# B6x register map
Vendor: XiaoMan; Series: B6 SOC; File version: 20260307
CPU: CM0+ r0p0, little endian, no MPU, no FPU, 2 interrupt priority bits
Registers are 32-bit, read-write, reset 0x0 unless marked. A register's access mark holds for its fields unless they carry their own. Offsets are from the block's base; [hi:lo] are bit positions.

## AON — Always On Domain
Base 0x40030000
0x00 BACKUP0 — valid-bit:16, can't be reset by pin reset, por12_bk_stb
0x04 BACKUP1 — valid-bit:8, can't be reset by pin reset, por12_bk_stb
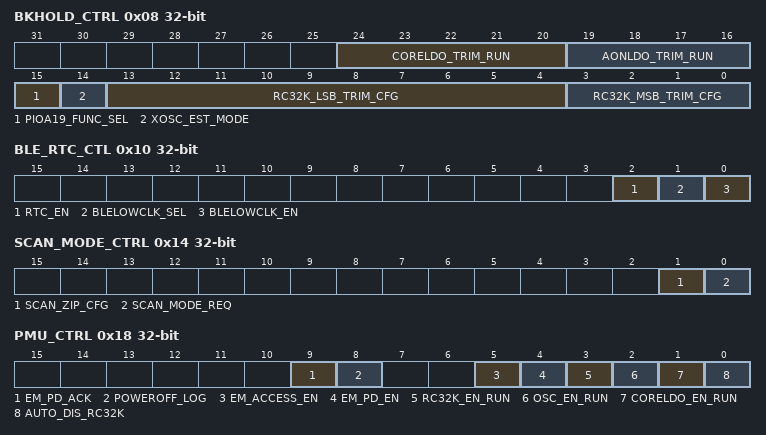
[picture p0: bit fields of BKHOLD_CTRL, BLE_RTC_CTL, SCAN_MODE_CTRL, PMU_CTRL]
0x08 BKHOLD_CTRL
  [24:20] CORELDO_TRIM_RUN — CORE LDO trim, used when ST_RUN
  [19:16] AONLDO_TRIM_RUN — LDOBK_TRIM, inverter the high two bits
  [15] PIOA19_FUNC_SEL
    1=Enable (pioa19 used as GPIO, can't be reset by pin reset); 0=Disable (pioa19 used as reset pin)
  [14] XOSC_EST_MODE
    1=Enable (extarnal clock through XOSC16M_IN PAD into chip and XOSC16M_OUT PAD is not driven by XOSC16M); 0=Disable (the XOSC16M_IN and XOSC16M_OUT are connected with crystal oscillator)
  [13:4] RC32K_LSB_TRIM_CFG
  [3:0] RC32K_MSB_TRIM_CFG
0x0C BACKUP2 — valid-bit:8, can't be reset by pin reset, por12_bk_stb
0x10 BLE_RTC_CTL
  [2] RTC_EN
    1=Enable (RTC enable); 0=Disable (RTC disable)
  [1] BLELOWCLK_SEL — BLE low power clock source select
    1=HES Div 32K (HSE clock/500); 0=RC32K Clock (lsi clock, 32K)
  [0] BLELOWCLK_EN
0x14 SCAN_MODE_CTRL — how to into scan mode 1: CPU write this scan_mode_req 2: wait 200us
  [1] SCAN_ZIP_CFG, [0] SCAN_MODE_REQ
0x18 PMU_CTRL — BLE_RTC_CTL register
  [9] EM_PD_ACK
  [8] POWEROFF_LOG — when is 1, chip is powerup from POWEROFF state, else means chip is initial powerup or powerup from BOD event happen
  [5] EM_ACCESS_EN — EM access enable
    1=EM is can be access; 0=EM is isolation
  [4] EM_PD_EN — EM power down or power enable
    1=EM is power down; 0=EN is power enable
  [3] RC32K_EN_RUN — only use when PMU in ST_RUN, RC32K
  [2] OSC_EN_RUN
  [1] CORELDO_EN_RUN
  [0] AUTO_DIS_RC32K — when auto_dis_rc32k is 1 RC32K is auto disable when chip in poweroff state or deepsleep state, RC32K is auto enable when wakeup event happen for poweroff state or deepsleep
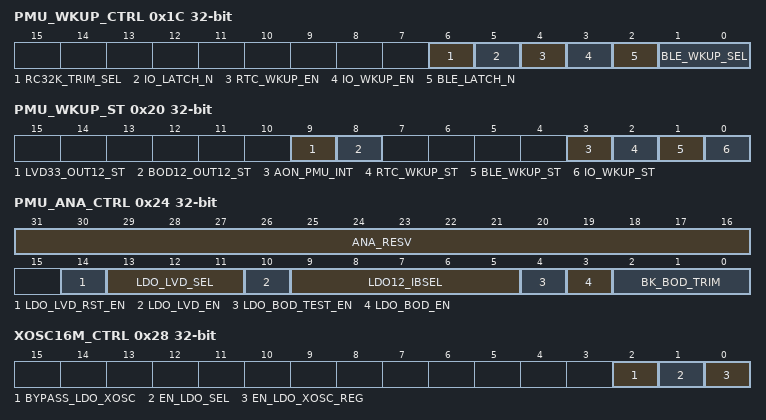
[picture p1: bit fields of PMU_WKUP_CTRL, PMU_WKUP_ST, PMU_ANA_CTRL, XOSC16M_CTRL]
0x1C PMU_WKUP_CTRL
  [6] RC32K_TRIM_SEL
    1=Enable (use RC32K calib result control the RC32K freq); 0=Disable (use rc32k_msb_trim_cfg and rc32k_lsb_trim_cfg control the RC32K freq)
  [5] IO_LATCH_N — config as 0 before chip into poweroff mode, set as 1 after chip powerup and retain the GPIO config
    1=enable the GPIO control signal from core to AON; 0=Disable (latch the GPIO control signal from core to AON)
  [4] RTC_WKUP_EN — both use when deepsleep or poweroff state
  [3] IO_WKUP_EN — both use when deepsleep or poweroff state
  [2] BLE_LATCH_N — config as 0 before chip into poweroff mode, set as 1 after chip powerup and retain the BB state
    1=enable the signal from BB to BLE LP counter; 0=Disable (latch the signal from BB to BLE LP counter)
  [1:0] BLE_WKUP_SEL — both use when deepsleep or poweroff state, when poweroff mode, only ble_osc_en can be used
    0=Disable Ble Wakeup; 1=Ble OSC_En Wakeup (select ble_osc_en as wakeup source); 2=Ble Radio_En Wakeup (select ble_radio_en as wakeup source); 3=Ble Lp Wakeup (select ble_wakeup_lp as wakeup source)
0x20 PMU_WKUP_ST
  [9] LVD33_OUT12_ST, [8] BOD12_OUT12_ST, [3] AON_PMU_INT, [2] RTC_WKUP_ST, [1] BLE_WKUP_ST, [0] IO_WKUP_ST
0x24 PMU_ANA_CTRL
  [31:16] ANA_RESV
  [14] LDO_LVD_RST_EN
  [13:11] LDO_LVD_SEL
  [10] LDO_LVD_EN
  [9:5] LDO12_IBSEL
  [4] LDO_BOD_TEST_EN
  [3] LDO_BOD_EN — detect the VDD12, when VDD12 little vth: BOD12_OUT12 is 1, else BOD12_OUT12 is 0
  [2:0] BK_BOD_TRIM
0x28 XOSC16M_CTRL
  [2] BYPASS_LDO_XOSC
  [1] EN_LDO_SEL — EN_LDO_XOSC control select
    1=EN_LDO_XOSC_REG (EN_LDO_XOSC is controlled by EN_LDO_XOSC_REG); 0=XOSC16M_EN (EN_LDO_XOSC is controlled by XOSC16M_EN)
  [0] EN_LDO_XOSC_REG

## FSHC — Flash Controller
Base 0x40006000
0x00 SPDR_RD — Date Read register
0x04 SPDR_WR — Data Write register
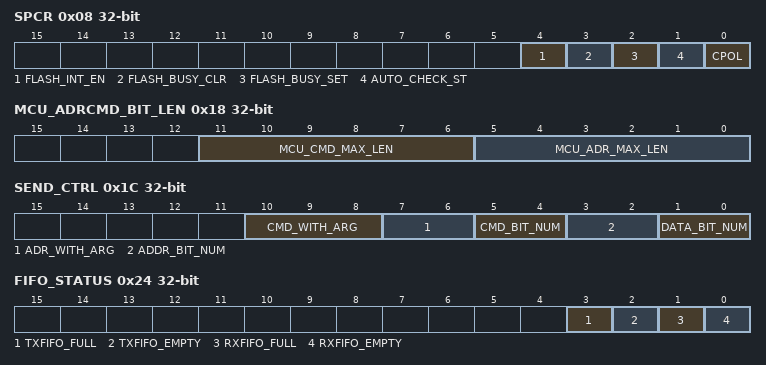
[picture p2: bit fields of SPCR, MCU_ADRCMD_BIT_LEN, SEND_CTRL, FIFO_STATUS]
0x08 SPCR — Control register
  [4] FLASH_INT_EN
  [3] FLASH_BUSY_CLR
  [2] FLASH_BUSY_SET
  [1] AUTO_CHECK_ST
  [0] CPOL — 1:negedge, 0:posedge
0x0C RXTX_DAT_LEN — Data Length register
0x10 CMD_REG — Cmd register
0x14 ADDR_REG — Address register
0x18 MCU_ADRCMD_BIT_LEN
  [11:6] MCU_CMD_MAX_LEN, [5:0] MCU_ADR_MAX_LEN
0x1C SEND_CTRL
  [10:8] CMD_WITH_ARG, [7:6] ADR_WITH_ARG, [5:4] CMD_BIT_NUM, [3:2] ADDR_BIT_NUM, [1:0] DATA_BIT_NUM
0x20 SEND_EN
0x24 FIFO_STATUS
  [3] TXFIFO_FULL, [2] TXFIFO_EMPTY, [1] RXFIFO_FULL, [0] RXFIFO_EMPTY
0x28 RXPTR_INC_EN
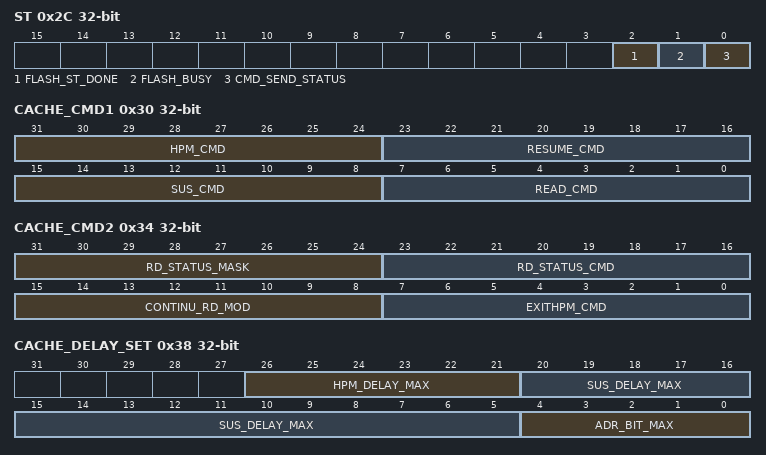
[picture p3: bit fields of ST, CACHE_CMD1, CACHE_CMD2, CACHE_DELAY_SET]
0x2C ST
  [2] FLASH_ST_DONE, [1] FLASH_BUSY, [0] CMD_SEND_STATUS
0x30 CACHE_CMD1
  [31:24] HPM_CMD, [23:16] RESUME_CMD, [15:8] SUS_CMD, [7:0] READ_CMD
0x34 CACHE_CMD2
  [31:24] RD_STATUS_MASK, [23:16] RD_STATUS_CMD, [15:8] CONTINU_RD_MOD, [7:0] EXITHPM_CMD
0x38 CACHE_DELAY_SET
  [26:21] HPM_DELAY_MAX, [20:5] SUS_DELAY_MAX, [4:0] ADR_BIT_MAX
0x3C CACHE_RESUME_DELAY_MAX
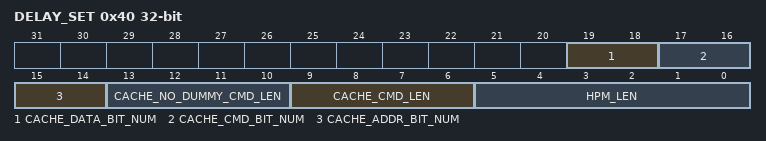
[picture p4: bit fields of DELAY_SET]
0x40 DELAY_SET
  [19:18] CACHE_DATA_BIT_NUM, [17:16] CACHE_CMD_BIT_NUM, [15:14] CACHE_ADDR_BIT_NUM, [13:10] CACHE_NO_DUMMY_CMD_LEN, [9:6] CACHE_CMD_LEN, [5:0] HPM_LEN
0x44 BYPASS_HPM
0x48 ATOM_OP_EN
0x4C CLR_HPM
0x50 CONTINUE_RD_MOD_INDEX
0x54 CONTINUE_STATUS
0x58 DLY_CFG
0x5C CACHE_ACCESS_STATUS
